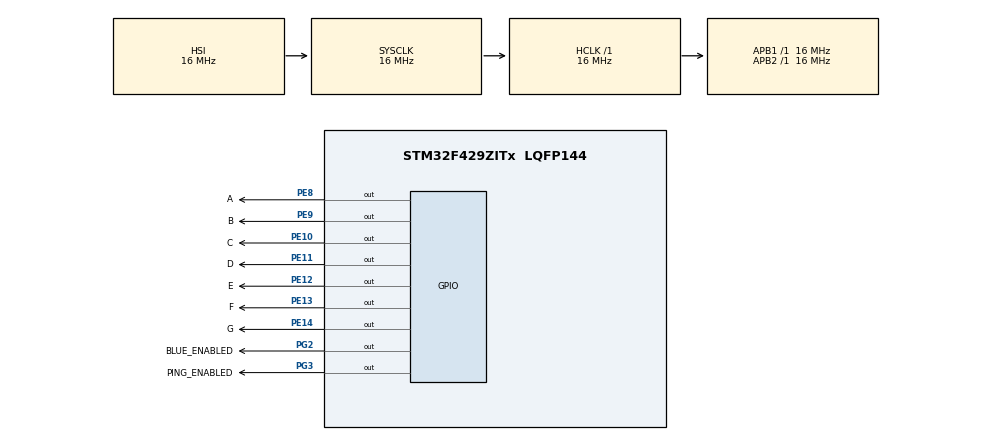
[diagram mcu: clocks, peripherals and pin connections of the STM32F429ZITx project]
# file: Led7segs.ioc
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Mcu.Family=STM32F4
Mcu.Name=STM32F429ZITx
Mcu.Package=LQFP144
NVIC.PriorityGroup=NVIC_PRIORITYGROUP_4
PE10.GPIO_Label=C
PE10.Signal=GPIO_Output
PE11.GPIO_Label=D
PE11.Signal=GPIO_Output
PE12.GPIO_Label=E
PE12.Signal=GPIO_Output
PE13.GPIO_Label=F
PE13.Signal=GPIO_Output
PE14.GPIO_Label=G
PE14.Signal=GPIO_Output
PE8.GPIO_Label=A
PE8.Signal=GPIO_Output
PE9.GPIO_Label=B
PE9.Signal=GPIO_Output
PG2.GPIO_Label=BLUE_ENABLED
PG2.Signal=GPIO_Output
PG3.GPIO_Label=PING_ENABLED
PG3.Signal=GPIO_Output
ProjectManager.HeapSize=0x200
ProjectManager.StackSize=0x400
ProjectManager.TargetToolchain=STM32CubeIDE
RCC.AHBFreq_Value=16000000
RCC.APB1Freq_Value=16000000
RCC.APB2Freq_Value=16000000
RCC.CortexFreq_Value=16000000
RCC.HSE_VALUE=25000000
RCC.HSI_VALUE=16000000
RCC.LSE_VALUE=32768
RCC.SYSCLKFreq_VALUE=16000000
RCC.VCOOutputFreq_Value=192000000
board=custom

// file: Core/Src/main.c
/* USER CODE BEGIN Header */
/**
  ******************************************************************************
  * @file           : main.c
  * @brief          : Main program body
  ******************************************************************************
  * @attention
  *
  * Copyright (c) 2025 STMicroelectronics.
  * All rights reserved.
  *
  * This software is licensed under terms that can be found in the LICENSE file
  * in the root directory of this software component.
  * If no LICENSE file comes with this software, it is provided AS-IS.
  *
  ******************************************************************************
  */
/* USER CODE END Header */
#include "main.h"

void SystemClock_Config(void);
static void MX_GPIO_Init(void);

int main(void)
{

  /* MCU Configuration--------------------------------------------------------*/

  /* Reset of all peripherals, Initializes the Flash interface and the Systick. */
  HAL_Init();

  /* Configure the system clock */
  SystemClock_Config();

  /* Initialize all configured peripherals */
  MX_GPIO_Init();
  /* USER CODE BEGIN 2 */
  HAL_GPIO_WritePin(A_GPIO_Port, A_Pin, GPIO_PIN_SET);
  HAL_GPIO_WritePin(B_GPIO_Port, B_Pin, GPIO_PIN_SET);
  HAL_GPIO_WritePin(C_GPIO_Port, C_Pin, GPIO_PIN_SET);
  HAL_GPIO_WritePin(D_GPIO_Port, D_Pin, GPIO_PIN_SET);
  HAL_GPIO_WritePin(E_GPIO_Port, E_Pin, GPIO_PIN_SET);
  HAL_GPIO_WritePin(F_GPIO_Port, F_Pin, GPIO_PIN_RESET);
  HAL_GPIO_WritePin(G_GPIO_Port, G_Pin, GPIO_PIN_RESET);

  ///Cho phép led 7-seg màu Ping sáng, bằng cách đưa logic 1 vào chân Base của transistor 2N2222, làm cực cathod của đèn nối liền với GND, thông mạch.
  HAL_GPIO_WritePin(PING_ENABLED_GPIO_Port, PING_ENABLED_Pin, GPIO_PIN_SET);
  HAL_Delay(1000);
  HAL_GPIO_WritePin(BLUE_ENABLED_GPIO_Port, BLUE_ENABLED_Pin, GPIO_PIN_SET);

  /* USER CODE END 2 */

  /* Infinite loop */
  while (1)
  {

  }
}

void SystemClock_Config(void)
{
  RCC_OscInitTypeDef RCC_OscInitStruct = {0};
  RCC_ClkInitTypeDef RCC_ClkInitStruct = {0};

  /** Configure the main internal regulator output voltage
  */
  __HAL_RCC_PWR_CLK_ENABLE();
  __HAL_PWR_VOLTAGESCALING_CONFIG(PWR_REGULATOR_VOLTAGE_SCALE3);

  /** Initializes the RCC Oscillators according to the specified parameters
  * in the RCC_OscInitTypeDef structure.
  */
  RCC_OscInitStruct.OscillatorType = RCC_OSCILLATORTYPE_HSI;
  RCC_OscInitStruct.HSIState = RCC_HSI_ON;
  RCC_OscInitStruct.HSICalibrationValue = RCC_HSICALIBRATION_DEFAULT;
  RCC_OscInitStruct.PLL.PLLState = RCC_PLL_NONE;
  if (HAL_RCC_OscConfig(&RCC_OscInitStruct) != HAL_OK)
  {
    Error_Handler();
  }

  /** Initializes the CPU, AHB and APB buses clocks
  */
  RCC_ClkInitStruct.ClockType = RCC_CLOCKTYPE_HCLK|RCC_CLOCKTYPE_SYSCLK
                              |RCC_CLOCKTYPE_PCLK1|RCC_CLOCKTYPE_PCLK2;
  RCC_ClkInitStruct.SYSCLKSource = RCC_SYSCLKSOURCE_HSI;
  RCC_ClkInitStruct.AHBCLKDivider = RCC_SYSCLK_DIV1;
  RCC_ClkInitStruct.APB1CLKDivider = RCC_HCLK_DIV1;
  RCC_ClkInitStruct.APB2CLKDivider = RCC_HCLK_DIV1;

  if (HAL_RCC_ClockConfig(&RCC_ClkInitStruct, FLASH_LATENCY_0) != HAL_OK)
  {
    Error_Handler();
  }
}

static void MX_GPIO_Init(void)
{
  GPIO_InitTypeDef GPIO_InitStruct = {0};

  /* GPIO Ports Clock Enable */
  __HAL_RCC_GPIOE_CLK_ENABLE();
  __HAL_RCC_GPIOG_CLK_ENABLE();

  /*Configure GPIO pin Output Level */
  HAL_GPIO_WritePin(GPIOE, A_Pin|B_Pin|C_Pin|D_Pin
                          |E_Pin|F_Pin|G_Pin, GPIO_PIN_RESET);

  /*Configure GPIO pin Output Level */
  HAL_GPIO_WritePin(GPIOG, BLUE_ENABLED_Pin|PING_ENABLED_Pin, GPIO_PIN_RESET);

  /*Configure GPIO pins : A_Pin B_Pin C_Pin D_Pin
                           E_Pin F_Pin G_Pin */
  GPIO_InitStruct.Pin = A_Pin|B_Pin|C_Pin|D_Pin
                          |E_Pin|F_Pin|G_Pin;
  GPIO_InitStruct.Mode = GPIO_MODE_OUTPUT_PP;
  GPIO_InitStruct.Pull = GPIO_NOPULL;
  GPIO_InitStruct.Speed = GPIO_SPEED_FREQ_LOW;
  HAL_GPIO_Init(GPIOE, &GPIO_InitStruct);

  /*Configure GPIO pins : BLUE_ENABLED_Pin PING_ENABLED_Pin */
  GPIO_InitStruct.Pin = BLUE_ENABLED_Pin|PING_ENABLED_Pin;
  GPIO_InitStruct.Mode = GPIO_MODE_OUTPUT_PP;
  GPIO_InitStruct.Pull = GPIO_NOPULL;
  GPIO_InitStruct.Speed = GPIO_SPEED_FREQ_LOW;
  HAL_GPIO_Init(GPIOG, &GPIO_InitStruct);

}

void Error_Handler(void)
{
  __disable_irq();
  while (1)
  {
  }
}
